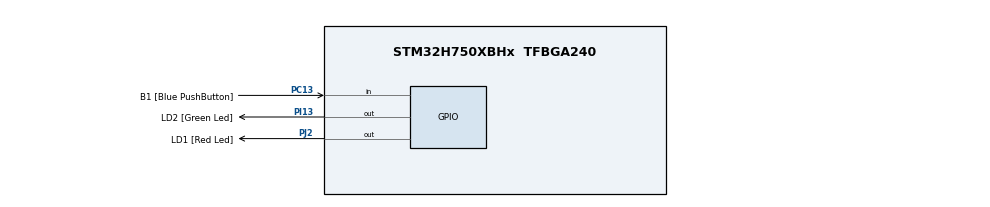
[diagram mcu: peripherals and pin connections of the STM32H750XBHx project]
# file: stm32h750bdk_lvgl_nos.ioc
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CORTEX_M7.AccessPermission-Cortex_Memory_Protection_Unit_Region0_Settings=MPU_REGION_FULL_ACCESS
CORTEX_M7.AccessPermission-Cortex_Memory_Protection_Unit_Region2_Settings=MPU_REGION_FULL_ACCESS
CORTEX_M7.AccessPermission-Cortex_Memory_Protection_Unit_Region4_Settings=MPU_REGION_FULL_ACCESS
CORTEX_M7.BaseAddress-Cortex_Memory_Protection_Unit_Region0_Settings=0x24000000
CORTEX_M7.BaseAddress-Cortex_Memory_Protection_Unit_Region1_Settings=0x90000000
CORTEX_M7.BaseAddress-Cortex_Memory_Protection_Unit_Region2_Settings=0x90000000
CORTEX_M7.BaseAddress-Cortex_Memory_Protection_Unit_Region3_Settings=0xD0000000
CORTEX_M7.BaseAddress-Cortex_Memory_Protection_Unit_Region4_Settings=0xD0000000
CORTEX_M7.CPU_DCache=Enabled
CORTEX_M7.CPU_ICache=Enabled
CORTEX_M7.DisableExec-Cortex_Memory_Protection_Unit_Region0_Settings=MPU_INSTRUCTION_ACCESS_DISABLE
CORTEX_M7.DisableExec-Cortex_Memory_Protection_Unit_Region1_Settings=MPU_INSTRUCTION_ACCESS_DISABLE
CORTEX_M7.DisableExec-Cortex_Memory_Protection_Unit_Region3_Settings=MPU_INSTRUCTION_ACCESS_DISABLE
CORTEX_M7.DisableExec-Cortex_Memory_Protection_Unit_Region4_Settings=MPU_INSTRUCTION_ACCESS_DISABLE
CORTEX_M7.Enable-Cortex_Memory_Protection_Unit_Region0_Settings=MPU_REGION_ENABLE
CORTEX_M7.Enable-Cortex_Memory_Protection_Unit_Region1_Settings=MPU_REGION_ENABLE
CORTEX_M7.Enable-Cortex_Memory_Protection_Unit_Region2_Settings=MPU_REGION_ENABLE
CORTEX_M7.Enable-Cortex_Memory_Protection_Unit_Region3_Settings=MPU_REGION_ENABLE
CORTEX_M7.Enable-Cortex_Memory_Protection_Unit_Region4_Settings=MPU_REGION_ENABLE
CORTEX_M7.IsBufferable-Cortex_Memory_Protection_Unit_Region0_Settings=MPU_ACCESS_BUFFERABLE
CORTEX_M7.IsBufferable-Cortex_Memory_Protection_Unit_Region2_Settings=MPU_ACCESS_BUFFERABLE
CORTEX_M7.IsCacheable-Cortex_Memory_Protection_Unit_Region0_Settings=MPU_ACCESS_CACHEABLE
CORTEX_M7.IsCacheable-Cortex_Memory_Protection_Unit_Region2_Settings=MPU_ACCESS_CACHEABLE
CORTEX_M7.IsCacheable-Cortex_Memory_Protection_Unit_Region4_Settings=MPU_ACCESS_CACHEABLE
CORTEX_M7.IsShareable-Cortex_Memory_Protection_Unit_Region0_Settings=MPU_ACCESS_NOT_SHAREABLE
CORTEX_M7.MPU_Control=MPU_PRIVILEGED_DEFAULT
CORTEX_M7.Size-Cortex_Memory_Protection_Unit_Region0_Settings=MPU_REGION_SIZE_512KB
CORTEX_M7.Size-Cortex_Memory_Protection_Unit_Region1_Settings=MPU_REGION_SIZE_256MB
CORTEX_M7.Size-Cortex_Memory_Protection_Unit_Region2_Settings=MPU_REGION_SIZE_128MB
CORTEX_M7.Size-Cortex_Memory_Protection_Unit_Region3_Settings=MPU_REGION_SIZE_256MB
CORTEX_M7.Size-Cortex_Memory_Protection_Unit_Region4_Settings=MPU_REGION_SIZE_32MB
Mcu.Family=STM32H7
Mcu.Name=STM32H750XBHx
Mcu.Package=TFBGA240
NVIC.PriorityGroup=NVIC_PRIORITYGROUP_4
NVIC.TIM6_DAC_IRQn=true\:15\:0\:false\:false\:true\:false\:true\:true
NVIC.TimeBase=TIM6_DAC_IRQn
NVIC.TimeBaseIP=TIM6
PA0_C.Signal=ADCx_INP0
PA1.GPIO_Label=MII_RX_CLK
PA1.Signal=ETH_RX_CLK
PA11.GPIO_Label=USB_OTG_FS2_N
PA11.Signal=USB_OTG_FS_DM
PA12.GPIO_Label=USB_OTG_FS2_P
PA12.Signal=USB_OTG_FS_DP
PA13\ (JTMS/SWDIO).Mode=Trace_Asynchronous_SW
PA13\ (JTMS/SWDIO).Signal=DEBUG_JTMS-SWDIO
PA14\ (JTCK/SWCLK).Mode=Trace_Asynchronous_SW
PA14\ (JTCK/SWCLK).Signal=DEBUG_JTCK-SWCLK
PA1_C.Signal=ADCx_INP1
PA2.GPIO_Label=MII_MDIO
PA2.Signal=ETH_MDIO
PA6.Signal=S_TIM13_CH1
PA7.GPIO_Label=MII_RX_DV
PA7.Signal=ETH_RX_DV
PA8.Signal=S_TIM1_CH1
PA9.GPIO_Label=VBUS_FS2
PA9.Signal=USB_OTG_FS_VBUS
PB0.GPIO_Label=MII_RX_D2
PB0.Signal=ETH_RXD2
PB1.GPIO_Label=MII_RX_D3
PB1.Signal=ETH_RXD3
PB10.GPIO_Label=VCP_TX
PB10.Signal=USART3_TX
PB11.GPIO_Label=VCP_RX
PB11.Signal=USART3_RX
PB13.GPIO_Label=FDCAN2_TX
PB13.Signal=FDCAN2_TX
PB15.Signal=SPI2_MOSI
PB3\ (JTDO/TRACESWO).Mode=Trace_Asynchronous_SW
PB3\ (JTDO/TRACESWO).Signal=DEBUG_JTDO-SWO
PB4\ (NJTRST).Signal=SPI2_NSS
PB5.GPIO_Label=FDCAN2_RX
PB5.Signal=FDCAN2_RX
PB8.GPIO_Label=SDIO1_D4
PB8.Signal=SDMMC1_D4
PB9.GPIO_Label=SDIO1_D5
PB9.Signal=SDMMC1_D5
PC0.Signal=ADCx_INP10
PC1.GPIO_Label=MII_MDC
PC1.Signal=ETH_MDC
PC10.GPIO_Label=SDIO1_D2
PC10.Signal=SDMMC1_D2
PC11.Signal=QUADSPI_BK2_NCS
PC12.GPIO_Label=SDIO1_CK
PC12.Signal=SDMMC1_CK
PC13.GPIO_Label=B1 [Blue PushButton]
PC13.Signal=GPIO_Input
PC14-OSC32_IN\ (OSC32_IN).GPIO_Label=OSC32_IN
PC14-OSC32_IN\ (OSC32_IN).Mode=LSE-External-Oscillator
PC14-OSC32_IN\ (OSC32_IN).Signal=RCC_OSC32_IN
PC15-OSC32_OUT\ (OSC32_OUT).GPIO_Label=OSC32_OUT
PC15-OSC32_OUT\ (OSC32_OUT).Mode=LSE-External-Oscillator
PC15-OSC32_OUT\ (OSC32_OUT).Signal=RCC_OSC32_OUT
PC2.GPIO_Label=MII_TXD2
PC2.Signal=ETH_TXD2
PC2_C.Signal=SharedAnalog_PC2
PC3.GPIO_Label=MII_TX_CLK
PC3.Signal=ETH_TX_CLK
PC3_C.Signal=ADC3_INP1
PC4.GPIO_Label=MII_RXD0
PC4.Signal=ETH_RXD0
PC5.GPIO_Label=MII_RXD1
PC5.Signal=ETH_RXD1
PC6.GPIO_Label=SDIO1_D6
PC6.Signal=SDMMC1_D6
PC7.GPIO_Label=SDIO1_D7
PC7.Signal=SDMMC1_D7
PC8.GPIO_Label=SDIO1_D0
PC8.Signal=SDMMC1_D0
PC9.GPIO_Label=SDIO1_D1
PC9.Signal=SDMMC1_D1
PD0.Signal=FMC_D2_DA2
PD1.Signal=FMC_D3_DA3
PD10.Signal=FMC_D15_DA15
PD11.GPIO_Speed=GPIO_SPEED_FREQ_VERY_HIGH
PD11.Signal=QUADSPI_BK1_IO0
PD12.Signal=I2C4_SCL
PD13.Signal=I2C4_SDA
PD14.Signal=FMC_D0_DA0
PD15.Signal=FMC_D1_DA1
PD2.GPIO_Label=SDIO1_CMD
PD2.Signal=SDMMC1_CMD
PD3.Signal=SPI2_SCK
PD8.Signal=FMC_D13_DA13
PD9.Signal=FMC_D14_DA14
PE0.Signal=FMC_NBL0
PE1.Signal=FMC_NBL1
PE10.Signal=FMC_D7_DA7
PE11.Signal=FMC_D8_DA8
PE12.Signal=FMC_D9_DA9
PE13.Signal=FMC_D10_DA10
PE14.Signal=FMC_D11_DA11
PE15.Signal=FMC_D12_DA12
PE2.GPIO_Label=MII_TXD3
PE2.Signal=ETH_TXD3
PE4.Signal=SAI4_D2
PE5.Signal=SAI4_CK2
PE7.Signal=FMC_D4_DA4
PE8.Signal=FMC_D5_DA5
PE9.Signal=FMC_D6_DA6
PF0.Signal=FMC_A0
PF1.Signal=FMC_A1
PF10.GPIO_Speed=GPIO_SPEED_FREQ_VERY_HIGH
PF10.Signal=QUADSPI_CLK
PF11.Signal=FMC_SDNRAS
PF12.Signal=FMC_A6
PF13.Signal=FMC_A7
PF14.Signal=FMC_A8
PF15.Signal=FMC_A9
PF2.Signal=FMC_A2
PF3.Signal=FMC_A3
PF4.Signal=FMC_A4
PF5.Signal=FMC_A5
PF6.GPIO_Speed=GPIO_SPEED_FREQ_VERY_HIGH
PF6.Signal=QUADSPI_BK1_IO3
PF7.GPIO_Speed=GPIO_SPEED_FREQ_VERY_HIGH
PF7.Signal=QUADSPI_BK1_IO2
PF8.Signal=ADC3_INP7
PF9.GPIO_Speed=GPIO_SPEED_FREQ_VERY_HIGH
PF9.Signal=QUADSPI_BK1_IO1
PG0.Signal=FMC_A10
PG1.Signal=FMC_A11
PG10.Signal=SAI2_SD_B
PG11.GPIO_Label=MII_TX_EN
PG11.Signal=ETH_TX_EN
PG12.GPIO_Label=MII_TXD1
PG12.Signal=ETH_TXD1
PG13.GPIO_Label=MII_TXD0
PG13.Signal=ETH_TXD0
PG15.Signal=FMC_SDNCAS
PG4.Signal=FMC_A14_BA0
PG5.Signal=FMC_A15_BA1
PG6.GPIO_PuPd=GPIO_PULLUP
PG6.GPIO_Speed=GPIO_SPEED_FREQ_VERY_HIGH
PG6.Signal=QUADSPI_BK1_NCS
PG8.Signal=FMC_SDCLK
PH0-OSC_IN\ (PH0).GPIO_Label=OSC_IN
PH0-OSC_IN\ (PH0).Mode=HSE-External-Clock-Source
PH0-OSC_IN\ (PH0).Signal=RCC_OSC_IN
PH1-OSC_OUT\ (PH1).GPIO_Label=OSC_OUT
PH1-OSC_OUT\ (PH1).Signal=RCC_OSC_OUT
PH13.GPIO_Label=FDCAN1_TX
PH13.Signal=FDCAN1_TX
PH14.GPIO_Label=FDCAN1_RX
PH14.Signal=FDCAN1_RX
PH15.Signal=TIM8_CH3N
PH2.GPIO_Speed=GPIO_SPEED_FREQ_VERY_HIGH
PH2.Signal=QUADSPI_BK2_IO0
PH3.GPIO_Speed=GPIO_SPEED_FREQ_VERY_HIGH
PH3.Signal=QUADSPI_BK2_IO1
PH5.Signal=FMC_SDNWE
PH6.Signal=FMC_SDNE1
PH7.Signal=FMC_SDCKE1
PH9.Signal=LTDC_R3
PI0.Signal=LTDC_G5
PI1.Signal=LTDC_G6
PI10.GPIO_Label=MII_RX_ER
PI10.Signal=ETH_RX_ER
PI12.Signal=LTDC_HSYNC
PI13.GPIO_Label=LD2 [Green Led]
PI13.Signal=GPIO_Output
PI14.Signal=LTDC_CLK
PI15.Signal=LTDC_R0
PI2.Signal=SPI2_MISO
PI4.Signal=SAI2_MCLK_A
PI5.Signal=SAI2_SCK_A
PI6.Signal=SAI2_SD_A
PI7.Signal=SAI2_FS_A
PI9.Signal=LTDC_VSYNC
PJ0.Signal=LTDC_R1
PJ1.Signal=LTDC_R2
PJ10.Signal=LTDC_G3
PJ11.Signal=LTDC_G4
PJ12.Signal=LTDC_B0
PJ13.Signal=LTDC_B1
PJ14.Signal=LTDC_B2
PJ15.GPIO_Label=LCD_DISP
PJ15.Signal=LTDC_B3
PJ2.GPIO_Label=LD1 [Red Led]
PJ2.Signal=GPIO_Output
PJ3.Signal=LTDC_R4
PJ4.Signal=LTDC_R5
PJ5.Signal=LTDC_R6
PJ6.Signal=LTDC_R7
PJ7.Signal=LTDC_G0
PJ8.Signal=LTDC_G1
PJ9.Signal=LTDC_G2
PK2.Signal=LTDC_G7
PK3.Signal=LTDC_B4
PK4.Signal=LTDC_B5
PK5.Signal=LTDC_B6
PK6.Signal=LTDC_B7
PK7.Signal=LTDC_DE
ProjectManager.HeapSize=0x2000
ProjectManager.StackSize=0x4000
ProjectManager.TargetToolchain=STM32CubeIDE
RCC.ADCFreq_Value=37500000
RCC.APB1Freq_Value=100000000
RCC.APB2Freq_Value=100000000
RCC.APB3Freq_Value=100000000
RCC.APB4Freq_Value=100000000
RCC.CortexFreq_Value=400000000
RCC.D1PPRE=RCC_APB3_DIV2
RCC.D2PPRE1=RCC_APB1_DIV2
RCC.D2PPRE2=RCC_APB2_DIV2
RCC.D3PPRE=RCC_APB4_DIV2
RCC.DIVM1=5
RCC.DIVM2=2
RCC.DIVM3=25
RCC.DIVN1=160
RCC.DIVN2=12
RCC.DIVN3=288
RCC.DIVP2=4
RCC.DIVQ1=4
RCC.HCLKFreq_Value=200000000
RCC.HPRE=RCC_HCLK_DIV2
RCC.PLL2FRACN=0
RCC.PLL3FRACN=0
RCC.PLLFRACN=0
RCC.PLLSourceVirtual=RCC_PLLSOURCE_HSE
RCC.ProductRev=revV
RCC.SYSCLKFreq_VALUE=400000000
RCC.SYSCLKSource=RCC_SYSCLKSOURCE_PLLCLK
RCC.USBFreq_Value=200000000
SH.ADCx_INP0.0=ADC1_INP0
SH.ADCx_INP0.1=ADC2_INP0
SH.ADCx_INP1.0=ADC1_INP1
SH.ADCx_INP1.1=ADC2_INP1
SH.ADCx_INP10.0=ADC1_INP10
SH.ADCx_INP10.1=ADC3_INP10
SH.FMC_A0.0=FMC_A0
SH.FMC_A1.0=FMC_A1
SH.FMC_A10.0=FMC_A10
SH.FMC_A11.0=FMC_A11
SH.FMC_A14_BA0.0=FMC_BA0
SH.FMC_A15_BA1.0=FMC_BA1
SH.FMC_A2.0=FMC_A2
SH.FMC_A3.0=FMC_A3
SH.FMC_A4.0=FMC_A4
SH.FMC_A5.0=FMC_A5
SH.FMC_A6.0=FMC_A6
SH.FMC_A7.0=FMC_A7
SH.FMC_A8.0=FMC_A8
SH.FMC_A9.0=FMC_A9
SH.FMC_D0_DA0.0=FMC_D0
SH.FMC_D10_DA10.0=FMC_D10
SH.FMC_D11_DA11.0=FMC_D11
SH.FMC_D12_DA12.0=FMC_D12
SH.FMC_D13_DA13.0=FMC_D13
SH.FMC_D14_DA14.0=FMC_D14
SH.FMC_D15_DA15.0=FMC_D15
SH.FMC_D1_DA1.0=FMC_D1
SH.FMC_D2_DA2.0=FMC_D2
SH.FMC_D3_DA3.0=FMC_D3
SH.FMC_D4_DA4.0=FMC_D4
SH.FMC_D5_DA5.0=FMC_D5
SH.FMC_D6_DA6.0=FMC_D6
SH.FMC_D7_DA7.0=FMC_D7
SH.FMC_D8_DA8.0=FMC_D8
SH.FMC_D9_DA9.0=FMC_D9
SH.FMC_NBL0.0=FMC_NBL0
SH.FMC_NBL1.0=FMC_NBL1
SH.FMC_SDCLK.0=FMC_SDCLK
SH.FMC_SDNCAS.0=FMC_SDNCAS
SH.FMC_SDNRAS.0=FMC_SDNRAS
SH.FMC_SDNWE.0=FMC_SDNWE
SH.S_TIM13_CH1.0=TIM13_CH1
SH.S_TIM1_CH1.0=TIM1_CH1
SH.SharedAnalog_PC2.0=ADC3_INP0
SH.SharedAnalog_PC2.1=ADC3_INN1
VP_SYS_VS_tim6.Mode=TIM6
board=STM32H750B-DK

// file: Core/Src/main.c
/* USER CODE BEGIN Header */
/**
  ******************************************************************************
  * @file           : main.c
  * @brief          : Main program body
  ******************************************************************************
  * @attention
  *
  * Copyright (c) 2023 STMicroelectronics.
  * All rights reserved.
  *
  * This software is licensed under terms that can be found in the LICENSE file
  * in the root directory of this software component.
  * If no LICENSE file comes with this software, it is provided AS-IS.
  *
  ******************************************************************************
  */
/* USER CODE END Header */
#include "main.h"

/* USER CODE BEGIN Includes */
#include "lvgl/lvgl.h"
#include "lvgl_port_lcd.h"
#include "lvgl_port_touchpad.h"
#include "lvgl/demos/lv_demos.h"
/* USER CODE END Includes */

void SystemClock_Config(void);
static void MPU_Initialize(void);
static void MPU_Config(void);
static void MX_GPIO_Init(void);

int main(void)
{

  /* Enable I-Cache---------------------------------------------------------*/
  SCB_EnableICache();

  /* Enable D-Cache---------------------------------------------------------*/
  SCB_EnableDCache();

  /* MCU Configuration--------------------------------------------------------*/

  /* Reset of all peripherals, Initializes the Flash interface and the Systick. */
  HAL_Init();

  /* MPU Configuration--------------------------------------------------------*/
  MPU_Config();

  /* Configure the system clock */
  SystemClock_Config();

  /* USER CODE BEGIN SysInit */
  /* Explicit enabling interrupt to support debugging in CubeIDE when using external flash loader */
  __enable_irq();
  /* USER CODE END SysInit */

  /* Initialize all configured peripherals */
  /* USER CODE BEGIN 2 */
  /* Functions auto-generated by CubeMX are not used here */
  BSP_LED_Init(LED_GREEN);
  BSP_LED_Init(LED_RED);

  /* Configure the User push-button in EXTI Mode */
  BSP_PB_Init(BUTTON_USER, BUTTON_MODE_EXTI);

  /* Configure Lvgl and LCD */
  lv_init();
  LCD_init();
  touchpad_init();
  lv_demo_widgets();

  /* USER CODE END 2 */

  /* Infinite loop */
  /* USER CODE BEGIN WHILE */
  while (1)
  {
    HAL_Delay(5);
    lv_task_handler();
    /* USER CODE END WHILE */

  }
}

void SystemClock_Config(void)
{
  RCC_OscInitTypeDef RCC_OscInitStruct = {0};
  RCC_ClkInitTypeDef RCC_ClkInitStruct = {0};

  /** Supply configuration update enable
  */
  HAL_PWREx_ConfigSupply(PWR_LDO_SUPPLY);

  /** Configure the main internal regulator output voltage
  */
  __HAL_PWR_VOLTAGESCALING_CONFIG(PWR_REGULATOR_VOLTAGE_SCALE1);

  while(!__HAL_PWR_GET_FLAG(PWR_FLAG_VOSRDY)) {}

  /** Initializes the RCC Oscillators according to the specified parameters
  * in the RCC_OscInitTypeDef structure.
  */
  RCC_OscInitStruct.OscillatorType = RCC_OSCILLATORTYPE_HSE;
  RCC_OscInitStruct.HSEState = RCC_HSE_BYPASS;
  RCC_OscInitStruct.PLL.PLLState = RCC_PLL_ON;
  RCC_OscInitStruct.PLL.PLLSource = RCC_PLLSOURCE_HSE;
  RCC_OscInitStruct.PLL.PLLM = 5;
  RCC_OscInitStruct.PLL.PLLN = 160;
  RCC_OscInitStruct.PLL.PLLP = 2;
  RCC_OscInitStruct.PLL.PLLQ = 4;
  RCC_OscInitStruct.PLL.PLLR = 2;
  RCC_OscInitStruct.PLL.PLLRGE = RCC_PLL1VCIRANGE_2;
  RCC_OscInitStruct.PLL.PLLVCOSEL = RCC_PLL1VCOWIDE;
  RCC_OscInitStruct.PLL.PLLFRACN = 0;
  if (HAL_RCC_OscConfig(&RCC_OscInitStruct) != HAL_OK)
  {
    Error_Handler();
  }

  /** Initializes the CPU, AHB and APB buses clocks
  */
  RCC_ClkInitStruct.ClockType = RCC_CLOCKTYPE_HCLK|RCC_CLOCKTYPE_SYSCLK
                              |RCC_CLOCKTYPE_PCLK1|RCC_CLOCKTYPE_PCLK2
                              |RCC_CLOCKTYPE_D3PCLK1|RCC_CLOCKTYPE_D1PCLK1;
  RCC_ClkInitStruct.SYSCLKSource = RCC_SYSCLKSOURCE_PLLCLK;
  RCC_ClkInitStruct.SYSCLKDivider = RCC_SYSCLK_DIV1;
  RCC_ClkInitStruct.AHBCLKDivider = RCC_HCLK_DIV2;
  RCC_ClkInitStruct.APB3CLKDivider = RCC_APB3_DIV2;
  RCC_ClkInitStruct.APB1CLKDivider = RCC_APB1_DIV2;
  RCC_ClkInitStruct.APB2CLKDivider = RCC_APB2_DIV2;
  RCC_ClkInitStruct.APB4CLKDivider = RCC_APB4_DIV2;

  if (HAL_RCC_ClockConfig(&RCC_ClkInitStruct, FLASH_LATENCY_2) != HAL_OK)
  {
    Error_Handler();
  }
}

static void MX_GPIO_Init(void)
{
  GPIO_InitTypeDef GPIO_InitStruct = {0};

  /* GPIO Ports Clock Enable */
  __HAL_RCC_GPIOI_CLK_ENABLE();
  __HAL_RCC_GPIOB_CLK_ENABLE();
  __HAL_RCC_GPIOK_CLK_ENABLE();
  __HAL_RCC_GPIOG_CLK_ENABLE();
  __HAL_RCC_GPIOC_CLK_ENABLE();
  __HAL_RCC_GPIOE_CLK_ENABLE();
  __HAL_RCC_GPIOJ_CLK_ENABLE();
  __HAL_RCC_GPIOD_CLK_ENABLE();
  __HAL_RCC_GPIOA_CLK_ENABLE();
  __HAL_RCC_GPIOH_CLK_ENABLE();
  __HAL_RCC_GPIOF_CLK_ENABLE();

  /*Configure GPIO pin Output Level */
  HAL_GPIO_WritePin(LD2_GPIO_Port, LD2_Pin, GPIO_PIN_RESET);

  /*Configure GPIO pin Output Level */
  HAL_GPIO_WritePin(LD1_GPIO_Port, LD1_Pin, GPIO_PIN_RESET);

  /*Configure GPIO pins : PI6 PI5 PI4 PI7 */
  GPIO_InitStruct.Pin = GPIO_PIN_6|GPIO_PIN_5|GPIO_PIN_4|GPIO_PIN_7;
  GPIO_InitStruct.Mode = GPIO_MODE_AF_PP;
  GPIO_InitStruct.Pull = GPIO_NOPULL;
  GPIO_InitStruct.Speed = GPIO_SPEED_FREQ_LOW;
  GPIO_InitStruct.Alternate = GPIO_AF10_SAI2;
  HAL_GPIO_Init(GPIOI, &GPIO_InitStruct);

  /*Configure GPIO pins : FDCAN2_RX_Pin FDCAN2_TX_Pin */
  GPIO_InitStruct.Pin = FDCAN2_RX_Pin|FDCAN2_TX_Pin;
  GPIO_InitStruct.Mode = GPIO_MODE_AF_PP;
  GPIO_InitStruct.Pull = GPIO_NOPULL;
  GPIO_InitStruct.Speed = GPIO_SPEED_FREQ_LOW;
  GPIO_InitStruct.Alternate = GPIO_AF9_FDCAN2;
  HAL_GPIO_Init(GPIOB, &GPIO_InitStruct);

  /*Configure GPIO pins : PK5 PK4 PK6 PK3
                           PK7 PK2 */
  GPIO_InitStruct.Pin = GPIO_PIN_5|GPIO_PIN_4|GPIO_PIN_6|GPIO_PIN_3
                          |GPIO_PIN_7|GPIO_PIN_2;
  GPIO_InitStruct.Mode = GPIO_MODE_AF_PP;
  GPIO_InitStruct.Pull = GPIO_NOPULL;
  GPIO_InitStruct.Speed = GPIO_SPEED_FREQ_LOW;
  GPIO_InitStruct.Alternate = GPIO_AF14_LTDC;
  HAL_GPIO_Init(GPIOK, &GPIO_InitStruct);

  /*Configure GPIO pin : PG10 */
  GPIO_InitStruct.Pin = GPIO_PIN_10;
  GPIO_InitStruct.Mode = GPIO_MODE_AF_PP;
  GPIO_InitStruct.Pull = GPIO_NOPULL;
  GPIO_InitStruct.Speed = GPIO_SPEED_FREQ_LOW;
  GPIO_InitStruct.Alternate = GPIO_AF10_SAI2;
  HAL_GPIO_Init(GPIOG, &GPIO_InitStruct);

  /*Configure GPIO pins : SDIO1_D2_Pin SDIO1_CK_Pin SDIO1_D0_Pin SDIO1_D1_Pin
                           SDIO1_D7_Pin SDIO1_D6_Pin */
  GPIO_InitStruct.Pin = SDIO1_D2_Pin|SDIO1_CK_Pin|SDIO1_D0_Pin|SDIO1_D1_Pin
                          |SDIO1_D7_Pin|SDIO1_D6_Pin;
  GPIO_InitStruct.Mode = GPIO_MODE_AF_PP;
  GPIO_InitStruct.Pull = GPIO_NOPULL;
  GPIO_InitStruct.Speed = GPIO_SPEED_FREQ_VERY_HIGH;
  GPIO_InitStruct.Alternate = GPIO_AF12_SDIO1;
  HAL_GPIO_Init(GPIOC, &GPIO_InitStruct);

  /*Configure GPIO pins : PI1 PI0 PI9 PI12
                           PI14 PI15 */
  GPIO_InitStruct.Pin = GPIO_PIN_1|GPIO_PIN_0|GPIO_PIN_9|GPIO_PIN_12
                          |GPIO_PIN_14|GPIO_PIN_15;
  GPIO_InitStruct.Mode = GPIO_MODE_AF_PP;
  GPIO_InitStruct.Pull = GPIO_NOPULL;
  GPIO_InitStruct.Speed = GPIO_SPEED_FREQ_LOW;
  GPIO_InitStruct.Alternate = GPIO_AF14_LTDC;
  HAL_GPIO_Init(GPIOI, &GPIO_InitStruct);

  /*Configure GPIO pins : PE1 PE0 PE10 PE9
                           PE11 PE12 PE15 PE8
                           PE13 PE7 PE14 */
  GPIO_InitStruct.Pin = GPIO_PIN_1|GPIO_PIN_0|GPIO_PIN_10|GPIO_PIN_9
                          |GPIO_PIN_11|GPIO_PIN_12|GPIO_PIN_15|GPIO_PIN_8
                          |GPIO_PIN_13|GPIO_PIN_7|GPIO_PIN_14;
  GPIO_InitStruct.Mode = GPIO_MODE_AF_PP;
  GPIO_InitStruct.Pull = GPIO_NOPULL;
  GPIO_InitStruct.Speed = GPIO_SPEED_FREQ_VERY_HIGH;
  GPIO_InitStruct.Alternate = GPIO_AF12_FMC;
  HAL_GPIO_Init(GPIOE, &GPIO_InitStruct);

  /*Configure GPIO pin : PB4 */
  GPIO_InitStruct.Pin = GPIO_PIN_4;
  GPIO_InitStruct.Mode = GPIO_MODE_AF_PP;
  GPIO_InitStruct.Pull = GPIO_NOPULL;
  GPIO_InitStruct.Speed = GPIO_SPEED_FREQ_LOW;
  GPIO_InitStruct.Alternate = GPIO_AF7_SPI2;
  HAL_GPIO_Init(GPIOB, &GPIO_InitStruct);

  /*Configure GPIO pins : MII_TX_EN_Pin MII_TXD1_Pin MII_TXD0_Pin */
  GPIO_InitStruct.Pin = MII_TX_EN_Pin|MII_TXD1_Pin|MII_TXD0_Pin;
  GPIO_InitStruct.Mode = GPIO_MODE_AF_PP;
  GPIO_InitStruct.Pull = GPIO_NOPULL;
  GPIO_InitStruct.Speed = GPIO_SPEED_FREQ_LOW;
  GPIO_InitStruct.Alternate = GPIO_AF11_ETH;
  HAL_GPIO_Init(GPIOG, &GPIO_InitStruct);

  /*Configure GPIO pins : LCD_DISP_Pin PJ14 PJ12 PJ13
                           PJ11 PJ10 PJ9 PJ0
                           PJ8 PJ7 PJ6 PJ1
                           PJ5 PJ3 PJ4 */
  GPIO_InitStruct.Pin = LCD_DISP_Pin|GPIO_PIN_14|GPIO_PIN_12|GPIO_PIN_13
                          |GPIO_PIN_11|GPIO_PIN_10|GPIO_PIN_9|GPIO_PIN_0
                          |GPIO_PIN_8|GPIO_PIN_7|GPIO_PIN_6|GPIO_PIN_1
                          |GPIO_PIN_5|GPIO_PIN_3|GPIO_PIN_4;
  GPIO_InitStruct.Mode = GPIO_MODE_AF_PP;
  GPIO_InitStruct.Pull = GPIO_NOPULL;
  GPIO_InitStruct.Speed = GPIO_SPEED_FREQ_LOW;
  GPIO_InitStruct.Alternate = GPIO_AF14_LTDC;
  HAL_GPIO_Init(GPIOJ, &GPIO_InitStruct);

  /*Configure GPIO pin : PD3 */
  GPIO_InitStruct.Pin = GPIO_PIN_3;
  GPIO_InitStruct.Mode = GPIO_MODE_AF_PP;
  GPIO_InitStruct.Pull = GPIO_NOPULL;
  GPIO_InitStruct.Speed = GPIO_SPEED_FREQ_LOW;
  GPIO_InitStruct.Alternate = GPIO_AF5_SPI2;
  HAL_GPIO_Init(GPIOD, &GPIO_InitStruct);

  /*Configure GPIO pin : PC11 */
  GPIO_InitStruct.Pin = GPIO_PIN_11;
  GPIO_InitStruct.Mode = GPIO_MODE_AF_PP;
  GPIO_InitStruct.Pull = GPIO_NOPULL;
  GPIO_InitStruct.Speed = GPIO_SPEED_FREQ_LOW;
  GPIO_InitStruct.Alternate = GPIO_AF9_QUADSPI;
  HAL_GPIO_Init(GPIOC, &GPIO_InitStruct);

  /*Configure GPIO pin : PI2 */
  GPIO_InitStruct.Pin = GPIO_PIN_2;
  GPIO_InitStruct.Mode = GPIO_MODE_AF_PP;
  GPIO_InitStruct.Pull = GPIO_NOPULL;
  GPIO_InitStruct.Speed = GPIO_SPEED_FREQ_LOW;
  GPIO_InitStruct.Alternate = GPIO_AF5_SPI2;
  HAL_GPIO_Init(GPIOI, &GPIO_InitStruct);

  /*Configure GPIO pin : PH15 */
  GPIO_InitStruct.Pin = GPIO_PIN_15;
  GPIO_InitStruct.Mode = GPIO_MODE_AF_PP;
  GPIO_InitStruct.Pull = GPIO_NOPULL;
  GPIO_InitStruct.Speed = GPIO_SPEED_FREQ_LOW;
  GPIO_InitStruct.Alternate = GPIO_AF3_TIM8;
  HAL_GPIO_Init(GPIOH, &GPIO_InitStruct);

  /*Configure GPIO pins : FDCAN1_RX_Pin FDCAN1_TX_Pin */
  GPIO_InitStruct.Pin = FDCAN1_RX_Pin|FDCAN1_TX_Pin;
  GPIO_InitStruct.Mode = GPIO_MODE_AF_PP;
  GPIO_InitStruct.Pull = GPIO_NOPULL;
  GPIO_InitStruct.Speed = GPIO_SPEED_FREQ_LOW;
  GPIO_InitStruct.Alternate = GPIO_AF9_FDCAN1;
  HAL_GPIO_Init(GPIOH, &GPIO_InitStruct);

  /*Configure GPIO pin : MII_TXD3_Pin */
  GPIO_InitStruct.Pin = MII_TXD3_Pin;
  GPIO_InitStruct.Mode = GPIO_MODE_AF_PP;
  GPIO_InitStruct.Pull = GPIO_NOPULL;
  GPIO_InitStruct.Speed = GPIO_SPEED_FREQ_LOW;
  GPIO_InitStruct.Alternate = GPIO_AF11_ETH;
  HAL_GPIO_Init(MII_TXD3_GPIO_Port, &GPIO_InitStruct);

  /*Configure GPIO pins : PE5 PE4 */
  GPIO_InitStruct.Pin = GPIO_PIN_5|GPIO_PIN_4;
  GPIO_InitStruct.Mode = GPIO_MODE_AF_PP;
  GPIO_InitStruct.Pull = GPIO_NOPULL;
  GPIO_InitStruct.Speed = GPIO_SPEED_FREQ_LOW;
  GPIO_InitStruct.Alternate = GPIO_AF10_SAI4;
  HAL_GPIO_Init(GPIOE, &GPIO_InitStruct);

  /*Configure GPIO pins : SDIO1_D5_Pin SDIO1_D4_Pin */
  GPIO_InitStruct.Pin = SDIO1_D5_Pin|SDIO1_D4_Pin;
  GPIO_InitStruct.Mode = GPIO_MODE_AF_PP;
  GPIO_InitStruct.Pull = GPIO_NOPULL;
  GPIO_InitStruct.Speed = GPIO_SPEED_FREQ_VERY_HIGH;
  GPIO_InitStruct.Alternate = GPIO_AF12_SDIO1;
  HAL_GPIO_Init(GPIOB, &GPIO_InitStruct);

  /*Configure GPIO pins : PG15 PG8 PG5 PG4
                           PG0 PG1 */
  GPIO_InitStruct.Pin = GPIO_PIN_15|GPIO_PIN_8|GPIO_PIN_5|GPIO_PIN_4
                          |GPIO_PIN_0|GPIO_PIN_1;
  GPIO_InitStruct.Mode = GPIO_MODE_AF_PP;
  GPIO_InitStruct.Pull = GPIO_NOPULL;
  GPIO_InitStruct.Speed = GPIO_SPEED_FREQ_VERY_HIGH;
  GPIO_InitStruct.Alternate = GPIO_AF12_FMC;
  HAL_GPIO_Init(GPIOG, &GPIO_InitStruct);

  /*Configure GPIO pin : SDIO1_CMD_Pin */
  GPIO_InitStruct.Pin = SDIO1_CMD_Pin;
  GPIO_InitStruct.Mode = GPIO_MODE_AF_PP;
  GPIO_InitStruct.Pull = GPIO_NOPULL;
  GPIO_InitStruct.Speed = GPIO_SPEED_FREQ_VERY_HIGH;
  GPIO_InitStruct.Alternate = GPIO_AF12_SDIO1;
  HAL_GPIO_Init(SDIO1_CMD_GPIO_Port, &GPIO_InitStruct);

  /*Configure GPIO pins : PD0 PD1 PD15 PD14
                           PD10 PD9 PD8 */
  GPIO_InitStruct.Pin = GPIO_PIN_0|GPIO_PIN_1|GPIO_PIN_15|GPIO_PIN_14
                          |GPIO_PIN_10|GPIO_PIN_9|GPIO_PIN_8;
  GPIO_InitStruct.Mode = GPIO_MODE_AF_PP;
  GPIO_InitStruct.Pull = GPIO_NOPULL;
  GPIO_InitStruct.Speed = GPIO_SPEED_FREQ_VERY_HIGH;
  GPIO_InitStruct.Alternate = GPIO_AF12_FMC;
  HAL_GPIO_Init(GPIOD, &GPIO_InitStruct);

  /*Configure GPIO pin : B1_Pin */
  GPIO_InitStruct.Pin = B1_Pin;
  GPIO_InitStruct.Mode = GPIO_MODE_INPUT;
  GPIO_InitStruct.Pull = GPIO_NOPULL;
  HAL_GPIO_Init(B1_GPIO_Port, &GPIO_InitStruct);

  /*Configure GPIO pin : PA8 */
  GPIO_InitStruct.Pin = GPIO_PIN_8;
  GPIO_InitStruct.Mode = GPIO_MODE_AF_PP;
  GPIO_InitStruct.Pull = GPIO_NOPULL;
  GPIO_InitStruct.Speed = GPIO_SPEED_FREQ_LOW;
  GPIO_InitStruct.Alternate = GPIO_AF1_TIM1;
  HAL_GPIO_Init(GPIOA, &GPIO_InitStruct);

  /*Configure GPIO pins : USB_OTG_FS2_P_Pin USB_OTG_FS2_N_Pin */
  GPIO_InitStruct.Pin = USB_OTG_FS2_P_Pin|USB_OTG_FS2_N_Pin;
  GPIO_InitStruct.Mode = GPIO_MODE_AF_PP;
  GPIO_InitStruct.Pull = GPIO_NOPULL;
  GPIO_InitStruct.Speed = GPIO_SPEED_FREQ_LOW;
  GPIO_InitStruct.Alternate = GPIO_AF10_OTG1_FS;
  HAL_GPIO_Init(GPIOA, &GPIO_InitStruct);

  /*Configure GPIO pin : MII_RX_ER_Pin */
  GPIO_InitStruct.Pin = MII_RX_ER_Pin;
  GPIO_InitStruct.Mode = GPIO_MODE_AF_PP;
  GPIO_InitStruct.Pull = GPIO_NOPULL;
  GPIO_InitStruct.Speed = GPIO_SPEED_FREQ_LOW;
  GPIO_InitStruct.Alternate = GPIO_AF11_ETH;
  HAL_GPIO_Init(MII_RX_ER_GPIO_Port, &GPIO_InitStruct);

  /*Configure GPIO pins : PF2 PF1 PF0 PF3
                           PF5 PF4 PF13 PF14
                           PF12 PF15 PF11 */
  GPIO_InitStruct.Pin = GPIO_PIN_2|GPIO_PIN_1|GPIO_PIN_0|GPIO_PIN_3
                          |GPIO_PIN_5|GPIO_PIN_4|GPIO_PIN_13|GPIO_PIN_14
                          |GPIO_PIN_12|GPIO_PIN_15|GPIO_PIN_11;
  GPIO_InitStruct.Mode = GPIO_MODE_AF_PP;
  GPIO_InitStruct.Pull = GPIO_NOPULL;
  GPIO_InitStruct.Speed = GPIO_SPEED_FREQ_VERY_HIGH;
  GPIO_InitStruct.Alternate = GPIO_AF12_FMC;
  HAL_GPIO_Init(GPIOF, &GPIO_InitStruct);

  /*Configure GPIO pin : PG6 */
  GPIO_InitStruct.Pin = GPIO_PIN_6;
  GPIO_InitStruct.Mode = GPIO_MODE_AF_PP;
  GPIO_InitStruct.Pull = GPIO_PULLUP;
  GPIO_InitStruct.Speed = GPIO_SPEED_FREQ_VERY_HIGH;
  GPIO_InitStruct.Alternate = GPIO_AF10_QUADSPI;
  HAL_GPIO_Init(GPIOG, &GPIO_InitStruct);

  /*Configure GPIO pin : LD2_Pin */
  GPIO_InitStruct.Pin = LD2_Pin;
  GPIO_InitStruct.Mode = GPIO_MODE_OUTPUT_PP;
  GPIO_InitStruct.Pull = GPIO_NOPULL;
  GPIO_InitStruct.Speed = GPIO_SPEED_FREQ_LOW;
  HAL_GPIO_Init(LD2_GPIO_Port, &GPIO_InitStruct);

  /*Configure GPIO pins : PF6 PF7 PF10 */
  GPIO_InitStruct.Pin = GPIO_PIN_6|GPIO_PIN_7|GPIO_PIN_10;
  GPIO_InitStruct.Mode = GPIO_MODE_AF_PP;
  GPIO_InitStruct.Pull = GPIO_NOPULL;
  GPIO_InitStruct.Speed = GPIO_SPEED_FREQ_VERY_HIGH;
  GPIO_InitStruct.Alternate = GPIO_AF9_QUADSPI;
  HAL_GPIO_Init(GPIOF, &GPIO_InitStruct);

  /*Configure GPIO pin : PF8 */
  GPIO_InitStruct.Pin = GPIO_PIN_8;
  GPIO_InitStruct.Mode = GPIO_MODE_ANALOG;
  GPIO_InitStruct.Pull = GPIO_NOPULL;
  HAL_GPIO_Init(GPIOF, &GPIO_InitStruct);

  /*Configure GPIO pin : PC0 */
  GPIO_InitStruct.Pin = GPIO_PIN_0;
  GPIO_InitStruct.Mode = GPIO_MODE_ANALOG;
  GPIO_InitStruct.Pull = GPIO_NOPULL;
  HAL_GPIO_Init(GPIOC, &GPIO_InitStruct);

  /*Configure GPIO pin : PF9 */
  GPIO_InitStruct.Pin = GPIO_PIN_9;
  GPIO_InitStruct.Mode = GPIO_MODE_AF_PP;
  GPIO_InitStruct.Pull = GPIO_NOPULL;
  GPIO_InitStruct.Speed = GPIO_SPEED_FREQ_VERY_HIGH;
  GPIO_InitStruct.Alternate = GPIO_AF10_QUADSPI;
  HAL_GPIO_Init(GPIOF, &GPIO_InitStruct);

  /*Configure GPIO pins : MII_MDC_Pin MII_TXD2_Pin MII_TX_CLK_Pin MII_RXD0_Pin
                           MII_RXD1_Pin */
  GPIO_InitStruct.Pin = MII_MDC_Pin|MII_TXD2_Pin|MII_TX_CLK_Pin|MII_RXD0_Pin
                          |MII_RXD1_Pin;
  GPIO_InitStruct.Mode = GPIO_MODE_AF_PP;
  GPIO_InitStruct.Pull = GPIO_NOPULL;
  GPIO_InitStruct.Speed = GPIO_SPEED_FREQ_LOW;
  GPIO_InitStruct.Alternate = GPIO_AF11_ETH;
  HAL_GPIO_Init(GPIOC, &GPIO_InitStruct);

  /*Configure GPIO pins : PH2 PH3 */
  GPIO_InitStruct.Pin = GPIO_PIN_2|GPIO_PIN_3;
  GPIO_InitStruct.Mode = GPIO_MODE_AF_PP;
  GPIO_InitStruct.Pull = GPIO_NOPULL;
  GPIO_InitStruct.Speed = GPIO_SPEED_FREQ_VERY_HIGH;
  GPIO_InitStruct.Alternate = GPIO_AF9_QUADSPI;
  HAL_GPIO_Init(GPIOH, &GPIO_InitStruct);

  /*Configure GPIO pins : MII_MDIO_Pin MII_RX_CLK_Pin MII_RX_DV_Pin */
  GPIO_InitStruct.Pin = MII_MDIO_Pin|MII_RX_CLK_Pin|MII_RX_DV_Pin;
  GPIO_InitStruct.Mode = GPIO_MODE_AF_PP;
  GPIO_InitStruct.Pull = GPIO_NOPULL;
  GPIO_InitStruct.Speed = GPIO_SPEED_FREQ_LOW;
  GPIO_InitStruct.Alternate = GPIO_AF11_ETH;
  HAL_GPIO_Init(GPIOA, &GPIO_InitStruct);

  /*Configure GPIO pins : PH5 PH6 PH7 */
  GPIO_InitStruct.Pin = GPIO_PIN_5|GPIO_PIN_6|GPIO_PIN_7;
  GPIO_InitStruct.Mode = GPIO_MODE_AF_PP;
  GPIO_InitStruct.Pull = GPIO_NOPULL;
  GPIO_InitStruct.Speed = GPIO_SPEED_FREQ_VERY_HIGH;
  GPIO_InitStruct.Alternate = GPIO_AF12_FMC;
  HAL_GPIO_Init(GPIOH, &GPIO_InitStruct);

  /*Configure GPIO pins : VCP_TX_Pin VCP_RX_Pin */
  GPIO_InitStruct.Pin = VCP_TX_Pin|VCP_RX_Pin;
  GPIO_InitStruct.Mode = GPIO_MODE_AF_PP;
  GPIO_InitStruct.Pull = GPIO_NOPULL;
  GPIO_InitStruct.Speed = GPIO_SPEED_FREQ_LOW;
  GPIO_InitStruct.Alternate = GPIO_AF7_USART3;
  HAL_GPIO_Init(GPIOB, &GPIO_InitStruct);

  /*Configure GPIO pin : PA6 */
  GPIO_InitStruct.Pin = GPIO_PIN_6;
  GPIO_InitStruct.Mode = GPIO_MODE_AF_PP;
  GPIO_InitStruct.Pull = GPIO_NOPULL;
  GPIO_InitStruct.Speed = GPIO_SPEED_FREQ_LOW;
  GPIO_InitStruct.Alternate = GPIO_AF9_TIM13;
  HAL_GPIO_Init(GPIOA, &GPIO_InitStruct);

  /*Configure GPIO pin : PH9 */
  GPIO_InitStruct.Pin = GPIO_PIN_9;
  GPIO_InitStruct.Mode = GPIO_MODE_AF_PP;
  GPIO_InitStruct.Pull = GPIO_NOPULL;
  GPIO_InitStruct.Speed = GPIO_SPEED_FREQ_LOW;
  GPIO_InitStruct.Alternate = GPIO_AF14_LTDC;
  HAL_GPIO_Init(GPIOH, &GPIO_InitStruct);

  /*Configure GPIO pin : PD11 */
  GPIO_InitStruct.Pin = GPIO_PIN_11;
  GPIO_InitStruct.Mode = GPIO_MODE_AF_PP;
  GPIO_InitStruct.Pull = GPIO_NOPULL;
  GPIO_InitStruct.Speed = GPIO_SPEED_FREQ_VERY_HIGH;
  GPIO_InitStruct.Alternate = GPIO_AF9_QUADSPI;
  HAL_GPIO_Init(GPIOD, &GPIO_InitStruct);

  /*Configure GPIO pins : PD12 PD13 */
  GPIO_InitStruct.Pin = GPIO_PIN_12|GPIO_PIN_13;
  GPIO_InitStruct.Mode = GPIO_MODE_AF_OD;
  GPIO_InitStruct.Pull = GPIO_NOPULL;
  GPIO_InitStruct.Speed = GPIO_SPEED_FREQ_LOW;
  GPIO_InitStruct.Alternate = GPIO_AF4_I2C4;
  HAL_GPIO_Init(GPIOD, &GPIO_InitStruct);

  /*Configure GPIO pins : MII_RX_D3_Pin MII_RX_D2_Pin */
  GPIO_InitStruct.Pin = MII_RX_D3_Pin|MII_RX_D2_Pin;
  GPIO_InitStruct.Mode = GPIO_MODE_AF_PP;
  GPIO_InitStruct.Pull = GPIO_NOPULL;
  GPIO_InitStruct.Speed = GPIO_SPEED_FREQ_LOW;
  GPIO_InitStruct.Alternate = GPIO_AF11_ETH;
  HAL_GPIO_Init(GPIOB, &GPIO_InitStruct);

  /*Configure GPIO pin : LD1_Pin */
  GPIO_InitStruct.Pin = LD1_Pin;
  GPIO_InitStruct.Mode = GPIO_MODE_OUTPUT_PP;
  GPIO_InitStruct.Pull = GPIO_NOPULL;
  GPIO_InitStruct.Speed = GPIO_SPEED_FREQ_LOW;
  HAL_GPIO_Init(LD1_GPIO_Port, &GPIO_InitStruct);

  /*Configure GPIO pin : PB15 */
  GPIO_InitStruct.Pin = GPIO_PIN_15;
  GPIO_InitStruct.Mode = GPIO_MODE_AF_PP;
  GPIO_InitStruct.Pull = GPIO_NOPULL;
  GPIO_InitStruct.Speed = GPIO_SPEED_FREQ_LOW;
  GPIO_InitStruct.Alternate = GPIO_AF5_SPI2;
  HAL_GPIO_Init(GPIOB, &GPIO_InitStruct);

  /*AnalogSwitch Config */
  HAL_SYSCFG_AnalogSwitchConfig(SYSCFG_SWITCH_PC2, SYSCFG_SWITCH_PC2_OPEN);

  /*AnalogSwitch Config */
  HAL_SYSCFG_AnalogSwitchConfig(SYSCFG_SWITCH_PC3, SYSCFG_SWITCH_PC3_OPEN);

  /*AnalogSwitch Config */
  HAL_SYSCFG_AnalogSwitchConfig(SYSCFG_SWITCH_PA0, SYSCFG_SWITCH_PA0_OPEN);

  /*AnalogSwitch Config */
  HAL_SYSCFG_AnalogSwitchConfig(SYSCFG_SWITCH_PA1, SYSCFG_SWITCH_PA1_OPEN);

}

/* USER CODE BEGIN 4 */

static void MPU_Initialize(void)
{

}

/* USER CODE END 4 */

/* MPU Configuration */

void MPU_Config(void)
{
  MPU_Region_InitTypeDef MPU_InitStruct = {0};

  /* Disables the MPU */
  HAL_MPU_Disable();

  /** Initializes and configures the Region and the memory to be protected
  */
  MPU_InitStruct.Enable = MPU_REGION_ENABLE;
  MPU_InitStruct.Number = MPU_REGION_NUMBER0;
  MPU_InitStruct.BaseAddress = 0x24000000;
  MPU_InitStruct.Size = MPU_REGION_SIZE_512KB;
  MPU_InitStruct.SubRegionDisable = 0x0;
  MPU_InitStruct.TypeExtField = MPU_TEX_LEVEL0;
  MPU_InitStruct.AccessPermission = MPU_REGION_FULL_ACCESS;
  MPU_InitStruct.DisableExec = MPU_INSTRUCTION_ACCESS_DISABLE;
  MPU_InitStruct.IsShareable = MPU_ACCESS_NOT_SHAREABLE;
  MPU_InitStruct.IsCacheable = MPU_ACCESS_CACHEABLE;
  MPU_InitStruct.IsBufferable = MPU_ACCESS_BUFFERABLE;

  HAL_MPU_ConfigRegion(&MPU_InitStruct);

  /** Initializes and configures the Region and the memory to be protected
  */
  MPU_InitStruct.Number = MPU_REGION_NUMBER1;
  MPU_InitStruct.BaseAddress = 0x90000000;
  MPU_InitStruct.Size = MPU_REGION_SIZE_256MB;
  MPU_InitStruct.AccessPermission = MPU_REGION_NO_ACCESS;
  MPU_InitStruct.IsCacheable = MPU_ACCESS_NOT_CACHEABLE;
  MPU_InitStruct.IsBufferable = MPU_ACCESS_NOT_BUFFERABLE;

  HAL_MPU_ConfigRegion(&MPU_InitStruct);

  /** Initializes and configures the Region and the memory to be protected
  */
  MPU_InitStruct.Number = MPU_REGION_NUMBER2;
  MPU_InitStruct.Size = MPU_REGION_SIZE_128MB;
  MPU_InitStruct.AccessPermission = MPU_REGION_FULL_ACCESS;
  MPU_InitStruct.DisableExec = MPU_INSTRUCTION_ACCESS_ENABLE;
  MPU_InitStruct.IsCacheable = MPU_ACCESS_CACHEABLE;
  MPU_InitStruct.IsBufferable = MPU_ACCESS_BUFFERABLE;

  HAL_MPU_ConfigRegion(&MPU_InitStruct);

  /** Initializes and configures the Region and the memory to be protected
  */
  MPU_InitStruct.Number = MPU_REGION_NUMBER3;
  MPU_InitStruct.BaseAddress = 0xD0000000;
  MPU_InitStruct.Size = MPU_REGION_SIZE_256MB;
  MPU_InitStruct.AccessPermission = MPU_REGION_NO_ACCESS;
  MPU_InitStruct.DisableExec = MPU_INSTRUCTION_ACCESS_DISABLE;
  MPU_InitStruct.IsCacheable = MPU_ACCESS_NOT_CACHEABLE;
  MPU_InitStruct.IsBufferable = MPU_ACCESS_NOT_BUFFERABLE;

  HAL_MPU_ConfigRegion(&MPU_InitStruct);

  /** Initializes and configures the Region and the memory to be protected
  */
  MPU_InitStruct.Number = MPU_REGION_NUMBER4;
  MPU_InitStruct.Size = MPU_REGION_SIZE_32MB;
  MPU_InitStruct.AccessPermission = MPU_REGION_FULL_ACCESS;
  MPU_InitStruct.IsCacheable = MPU_ACCESS_CACHEABLE;

  HAL_MPU_ConfigRegion(&MPU_InitStruct);
  /* Enables the MPU */
  HAL_MPU_Enable(MPU_PRIVILEGED_DEFAULT);

}

void HAL_TIM_PeriodElapsedCallback(TIM_HandleTypeDef *htim)
{
  if (htim->Instance == TIM6) {
    HAL_IncTick();
  }
  /* USER CODE BEGIN Callback 1 */
  if (htim->Instance == TIM6)
  {
    /* Lvgl Tick */
    lv_tick_inc(1);
  }

  /* USER CODE END Callback 1 */
}

void Error_Handler(void)
{
  __disable_irq();
  while (1)
  {
  }
}
